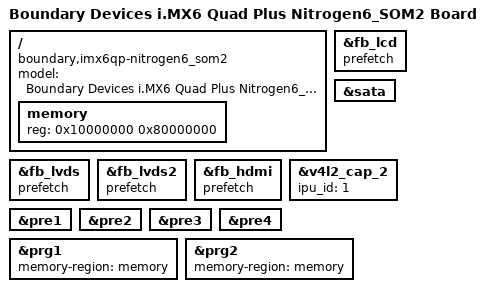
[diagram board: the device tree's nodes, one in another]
// SPDX-License-Identifier: GPL-2.0 OR X11
/*
 * Copyright 2017 Boundary Devices, Inc.
 */

/dts-v1/;

#include <dt-bindings/interrupt-controller/irq.h>
#include "imx6qp.dtsi"
#include "imx6qdl-nitrogen6_som2.dtsi"

/ {
	model = "Boundary Devices i.MX6 Quad Plus Nitrogen6_SOM2 Board";
	compatible = "boundary,imx6qp-nitrogen6_som2", "fsl,imx6qp";

	memory: memory {
		reg = <0x10000000 0x80000000>;
	};
};

&fb_lvds {
	prefetch;
};

&fb_lvds2 {
	prefetch;
};

&fb_lcd {
	prefetch;
};

&fb_hdmi {
	prefetch;
};

&sata {
	status = "okay";
};

&v4l2_cap_2 {
	ipu_id = <1>;
};

&pre1 {
	status = "okay";
};

&pre2 {
	status = "okay";
};

&pre3 {
	status = "okay";
};

&pre4 {
	status = "okay";
};

&prg1 {
	memory-region = <&memory>;
	status = "okay";
};

&prg2 {
	memory-region = <&memory>;
	status = "okay";
};
